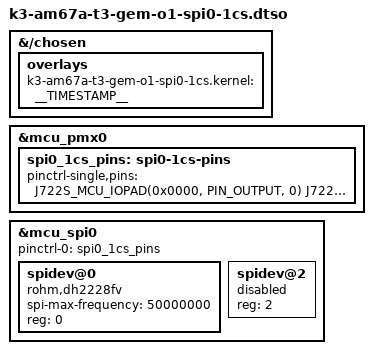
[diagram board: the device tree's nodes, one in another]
// SPDX-License-Identifier: GPL-2.0
/*
 * DT Overlay for spi0-1cs on t3-gem-o1 board.
 *
 * Copyright (C) 2023 Texas Instruments Incorporated - https://www.ti.com/
 *
 */

/dts-v1/;
/plugin/;

#include <dt-bindings/gpio/gpio.h>
#include "k3-pinctrl.h"

/*
 * Helper to show loaded overlays under: /proc/device-tree/chosen/overlays/
 */
&{/chosen} {
	overlays {
		k3-am67a-t3-gem-o1-spi0-1cs.kernel = __TIMESTAMP__;
	};
};

&mcu_pmx0 {
	spi0_1cs_pins: spi0-1cs-pins {
		pinctrl-single,pins = <
			J722S_MCU_IOPAD(0x0000, PIN_OUTPUT, 0) /* (C12) MCU_SPI0_CS0 */
			J722S_MCU_IOPAD(0x0004, PIN_OUTPUT, 0) /* (A10) MCU_SPI0_CS1 */
			J722S_MCU_IOPAD(0x0034, PIN_OUTPUT, 2) /* (B2) MCU_SPI0_CS3 */
			J722S_MCU_IOPAD(0x0008, PIN_OUTPUT, 0) /* (A9) MCU_SPI0_CLK */
			J722S_MCU_IOPAD(0x000C, PIN_OUTPUT, 0) /* (B12) MCU_SPI0_D0 */
			J722S_MCU_IOPAD(0x0010, PIN_INPUT, 0)  /* (C11) MCU_SPI0_D1 */
			J722S_MCU_IOPAD(0x0030, PIN_OUTPUT, 7) /* (C3) WKUP_UART0_RTSn.MCU_GPIO0_12 */
		>;
		bootph-all;
	};
};

&mcu_spi0 {
	pinctrl-0 = <&spi0_1cs_pins>;

	// Need these lines to get rid of dtc warnings
	#address-cells = <1>;
	#size-cells = <0>;

	// HAT CS0
	spidev@0 {
		spi-max-frequency = <50000000>;
		reg = <0>;
		compatible = "rohm,dh2228fv";
	};

	// HAT CS1
	spidev@2 {
		reg = <2>;
		status = "disabled";
	};
};
